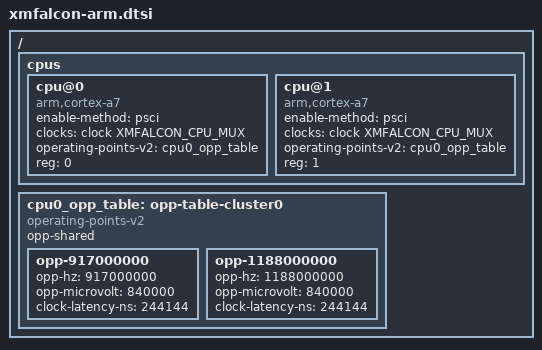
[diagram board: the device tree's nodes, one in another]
// SPDX-License-Identifier: GPL-2.0

/{
	cpus {
		#address-cells = <1>;
		#size-cells = <0>;
		/* enable-method = "lotus,xmfalcon-smp"; */

		cpu@0 {
			device_type = "cpu";
			compatible = "arm,cortex-a7";
			enable-method = "psci";
			clocks = <&clock XMFALCON_CPU_MUX>;
			clock-names = "cpu";
			operating-points-v2 = <&cpu0_opp_table>;
			reg = <0>;
		};

		cpu@1 {
			device_type = "cpu";
			compatible = "arm,cortex-a7";
			enable-method = "psci";
			clocks = <&clock XMFALCON_CPU_MUX>;
			clock-names = "cpu";
			operating-points-v2 = <&cpu0_opp_table>;
			reg = <1>;
		};
	};

	cpu0_opp_table: opp-table-cluster0 {
		compatible = "operating-points-v2";
		opp-shared;

		opp-917000000 {
			opp-hz = /bits/ 64 <917000000>;
			opp-microvolt = <840000>;
			clock-latency-ns = <244144>; /* 8 32k periods */
		};
		opp-1188000000 {
			opp-hz = /bits/ 64 <1188000000>;
			opp-microvolt = <840000>;
			clock-latency-ns = <244144>; /* 8 32k periods */
		};
	};
};
